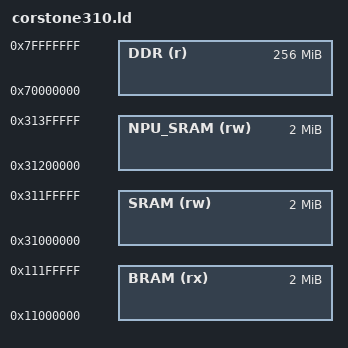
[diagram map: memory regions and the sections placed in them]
/* SPDX-License-Identifier: BSD-3-Clause */
MEMORY {
    BRAM (rx) : ORIGIN = 0x11000000, LENGTH = 2M
    SRAM (rw) : ORIGIN = 0x31000000, LENGTH = 2M
    NPU_SRAM (rw) : ORIGIN = 0x31200000, LENGTH = 2M
    DDR (r) : ORIGIN = 0x70000000, LENGTH = 256M
}
REGION_ALIAS("BOOT", BRAM);
REGION_ALIAS("CODE", BRAM);
REGION_ALIAS("DATA", SRAM);
